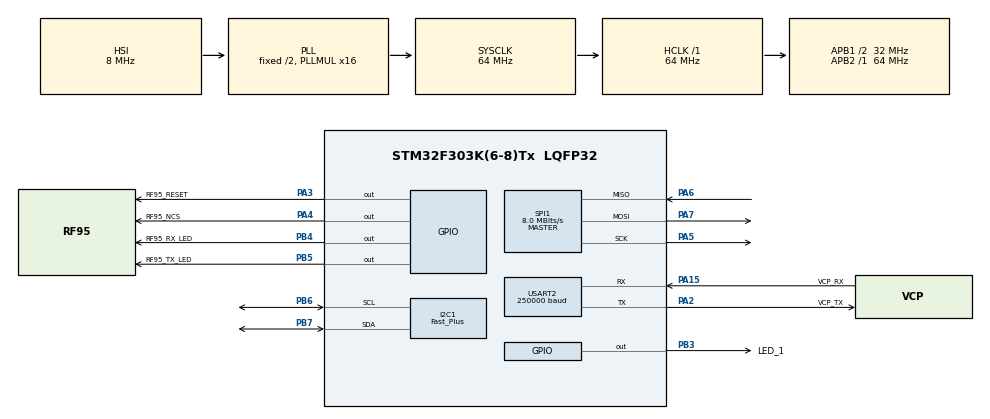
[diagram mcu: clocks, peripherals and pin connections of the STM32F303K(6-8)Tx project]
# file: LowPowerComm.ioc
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I2C1.I2C_Speed_Mode=I2C_Fast_Plus
I2C1.Timing=0x00100001
Mcu.Family=STM32F3
Mcu.Name=STM32F303K(6-8)Tx
Mcu.Package=LQFP32
NVIC.PriorityGroup=NVIC_PRIORITYGROUP_4
NVIC.TIM1_UP_TIM16_IRQn=true\:15\:0\:false\:false\:true\:false\:true\:true
NVIC.TimeBase=TIM1_UP_TIM16_IRQn
NVIC.TimeBaseIP=TIM1
PA13.GPIO_Label=SWDIO
PA13.Mode=Serial_Wire
PA13.Signal=SYS_JTMS-SWDIO
PA14.GPIO_Label=SWCLK
PA14.Mode=Serial_Wire
PA14.Signal=SYS_JTCK-SWCLK
PA15.GPIO_Label=VCP_RX
PA15.Mode=Asynchronous
PA15.Signal=USART2_RX
PA2.GPIO_Label=VCP_TX
PA2.Mode=Asynchronous
PA2.Signal=USART2_TX
PA3.GPIO_Label=RF95_RESET
PA3.GPIO_PuPd=GPIO_PULLDOWN
PA3.PinState=GPIO_PIN_RESET
PA3.Signal=GPIO_Output
PA4.GPIO_Label=RF95_NCS
PA4.GPIO_PuPd=GPIO_PULLUP
PA4.Signal=GPIO_Output
PA5.GPIO_PuPd=GPIO_PULLDOWN
PA5.Mode=Full_Duplex_Master
PA5.Signal=SPI1_SCK
PA6.GPIO_PuPd=GPIO_PULLDOWN
PA6.Mode=Full_Duplex_Master
PA6.Signal=SPI1_MISO
PA7.GPIO_PuPd=GPIO_PULLDOWN
PA7.Mode=Full_Duplex_Master
PA7.Signal=SPI1_MOSI
PB3.GPIO_Label=LED_1
PB3.Signal=GPIO_Output
PB4.GPIO_Label=RF95_RX_LED
PB4.Signal=GPIO_Output
PB5.GPIO_Label=RF95_TX_LED
PB5.Signal=GPIO_Output
PB6.GPIO_FM6=SYSCFG_CFGR1_I2C_PB6_FMP
PB6.GPIO_Pu=GPIO_PULLUP
PB6.Mode=I2C
PB6.Signal=I2C1_SCL
PB7.GPIO_FM7=SYSCFG_CFGR1_I2C_PB7_FMP
PB7.GPIO_Pu=GPIO_PULLUP
PB7.Mode=I2C
PB7.Signal=I2C1_SDA
PF0\ /\ OSC_IN.GPIO_Label=MCO
PF0\ /\ OSC_IN.Mode=HSE-External-Clock-Source
PF0\ /\ OSC_IN.Signal=RCC_OSC_IN
ProjectManager.HeapSize=0x200
ProjectManager.StackSize=0x400
ProjectManager.TargetToolchain=CMake
RCC.AHBFreq_Value=64000000
RCC.APB1CLKDivider=RCC_HCLK_DIV2
RCC.APB1Freq_Value=32000000
RCC.APB1TimFreq_Value=64000000
RCC.APB2Freq_Value=64000000
RCC.APB2TimFreq_Value=64000000
RCC.CortexFreq_Value=64000000
RCC.HCLKFreq_Value=64000000
RCC.HSE_VALUE=8000000
RCC.HSI_VALUE=8000000
RCC.PLLMUL=RCC_PLL_MUL16
RCC.SYSCLKFreq_VALUE=64000000
RCC.SYSCLKSourceVirtual=RCC_SYSCLKSOURCE_PLLCLK
SPI1.BaudRatePrescaler=SPI_BAUDRATEPRESCALER_8
SPI1.CLKPhase=SPI_PHASE_1EDGE
SPI1.CLKPolarity=SPI_POLARITY_LOW
SPI1.CalculateBaudRate=8.0 MBits/s
SPI1.DataSize=SPI_DATASIZE_8BIT
SPI1.Direction=SPI_DIRECTION_2LINES
SPI1.Mode=SPI_MODE_MASTER
SPI1.VirtualType=VM_MASTER
USART2.BaudRate=250000
USART2.VirtualMode-Asynchronous=VM_ASYNC
VP_SYS_VS_tim1.Mode=TIM1
board=NUCLEO-F303K8

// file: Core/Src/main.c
/* USER CODE BEGIN Header */
/**
  ******************************************************************************
  * @file           : main.c
  * @brief          : Main program body
  ******************************************************************************
  * @attention
  *
  * Copyright (c) 2024 STMicroelectronics.
  * All rights reserved.
  *
  * This software is licensed under terms that can be found in the LICENSE file
  * in the root directory of this software component.
  * If no LICENSE file comes with this software, it is provided AS-IS.
  *
  ******************************************************************************
  */
/* USER CODE END Header */
#include "main.h"
#include "i2c.h"
#include "spi.h"
#include "usart.h"
#include "gpio.h"

/* USER CODE BEGIN Includes */

#include "string.h"
#include "../RTTViewer/SEGGER_RTT.h"
//#include "../OLED/display.h"
#include "../Sensor/Presence.h"
#include "../RF95/RF95.h"

/* USER CODE END Includes */

/* USER CODE BEGIN PD */
#define RTT_PRINTF_BUFFER_SIZE 64
/* USER CODE END PD */

void SystemClock_Config(void);

int main(void)
{

  /* USER CODE BEGIN 1 */
  char abDataIn[RTT_PRINTF_BUFFER_SIZE];
  char abDataOut[RTT_PRINTF_BUFFER_SIZE];
  size_t a=0;

  /* USER CODE END 1 */

  /* MCU Configuration--------------------------------------------------------*/

  /* Reset of all peripherals, Initializes the Flash interface and the Systick. */
  HAL_Init();

  /* Configure the system clock */
  SystemClock_Config();

  /* Initialize all configured peripherals */
  MX_GPIO_Init();
  MX_USART2_UART_Init();
  MX_I2C1_Init();
  MX_SPI1_Init();
  /* USER CODE BEGIN 2 */
  HAL_UART_Init(&huart2);
  SEGGER_RTT_Init();
  SEGGER_RTT_SetTerminal(0);
  SEGGER_RTT_ConfigDownBuffer(1, "DataIn", &abDataIn[0], sizeof(abDataIn), SEGGER_RTT_MODE_NO_BLOCK_SKIP);
  SEGGER_RTT_ConfigUpBuffer(1, "DataOut", &abDataOut[0], sizeof(abDataOut), SEGGER_RTT_MODE_BLOCK_IF_FIFO_FULL);
  RF95_Init();

  /* USER CODE END 2 */

  /* Infinite loop */
  while (1)
  {

  }
}

void SystemClock_Config(void)
{
  RCC_OscInitTypeDef RCC_OscInitStruct = {0};
  RCC_ClkInitTypeDef RCC_ClkInitStruct = {0};
  RCC_PeriphCLKInitTypeDef PeriphClkInit = {0};

  /** Initializes the RCC Oscillators according to the specified parameters
  * in the RCC_OscInitTypeDef structure.
  */
  RCC_OscInitStruct.OscillatorType = RCC_OSCILLATORTYPE_HSI;
  RCC_OscInitStruct.HSIState = RCC_HSI_ON;
  RCC_OscInitStruct.HSICalibrationValue = RCC_HSICALIBRATION_DEFAULT;
  RCC_OscInitStruct.PLL.PLLState = RCC_PLL_ON;
  RCC_OscInitStruct.PLL.PLLSource = RCC_PLLSOURCE_HSI;
  RCC_OscInitStruct.PLL.PLLMUL = RCC_PLL_MUL16;
  if (HAL_RCC_OscConfig(&RCC_OscInitStruct) != HAL_OK)
  {
    Error_Handler();
  }

  /** Initializes the CPU, AHB and APB buses clocks
  */
  RCC_ClkInitStruct.ClockType = RCC_CLOCKTYPE_HCLK|RCC_CLOCKTYPE_SYSCLK
                              |RCC_CLOCKTYPE_PCLK1|RCC_CLOCKTYPE_PCLK2;
  RCC_ClkInitStruct.SYSCLKSource = RCC_SYSCLKSOURCE_PLLCLK;
  RCC_ClkInitStruct.AHBCLKDivider = RCC_SYSCLK_DIV1;
  RCC_ClkInitStruct.APB1CLKDivider = RCC_HCLK_DIV2;
  RCC_ClkInitStruct.APB2CLKDivider = RCC_HCLK_DIV1;

  if (HAL_RCC_ClockConfig(&RCC_ClkInitStruct, FLASH_LATENCY_2) != HAL_OK)
  {
    Error_Handler();
  }
  PeriphClkInit.PeriphClockSelection = RCC_PERIPHCLK_I2C1;
  PeriphClkInit.I2c1ClockSelection = RCC_I2C1CLKSOURCE_HSI;
  if (HAL_RCCEx_PeriphCLKConfig(&PeriphClkInit) != HAL_OK)
  {
    Error_Handler();
  }
}

void HAL_TIM_PeriodElapsedCallback(TIM_HandleTypeDef *htim)
{
  if (htim->Instance == TIM1) {
    HAL_IncTick();
  }
}

void Error_Handler(void)
{
  __disable_irq();
  while (1)
  {
  }
}
